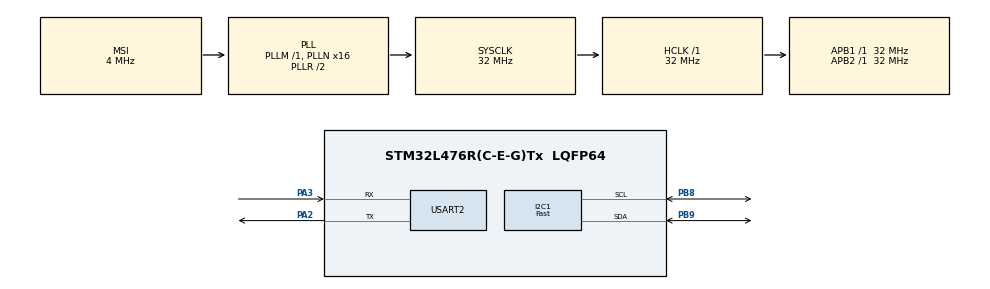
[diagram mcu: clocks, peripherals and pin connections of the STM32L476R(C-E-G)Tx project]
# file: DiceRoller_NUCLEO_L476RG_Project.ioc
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I2C1.I2C_Speed_Mode=I2C_Fast
I2C1.Timing=0x0060112F
Mcu.Family=STM32L4
Mcu.Name=STM32L476R(C-E-G)Tx
Mcu.Package=LQFP64
NVIC.PriorityGroup=NVIC_PRIORITYGROUP_4
PA13\ (JTMS-SWDIO).Mode=Serial_Wire
PA13\ (JTMS-SWDIO).Signal=SYS_JTMS-SWDIO
PA14\ (JTCK-SWCLK).Mode=Serial_Wire
PA14\ (JTCK-SWCLK).Signal=SYS_JTCK-SWCLK
PA2.Mode=Asynchronous
PA2.Signal=USART2_TX
PA3.Mode=Asynchronous
PA3.Signal=USART2_RX
PB8.Mode=I2C
PB8.Signal=I2C1_SCL
PB9.Mode=I2C
PB9.Signal=I2C1_SDA
PC14-OSC32_IN\ (PC14).Mode=LSE-External-Oscillator
PC14-OSC32_IN\ (PC14).Signal=RCC_OSC32_IN
PC15-OSC32_OUT\ (PC15).Mode=LSE-External-Oscillator
PC15-OSC32_OUT\ (PC15).Signal=RCC_OSC32_OUT
ProjectManager.HeapSize=0x200
ProjectManager.StackSize=0x400
ProjectManager.TargetToolchain=STM32CubeIDE
RCC.AHBFreq_Value=32000000
RCC.APB1Freq_Value=32000000
RCC.APB1TimFreq_Value=32000000
RCC.APB2Freq_Value=32000000
RCC.APB2TimFreq_Value=32000000
RCC.CortexFreq_Value=32000000
RCC.HCLKFreq_Value=32000000
RCC.HSE_VALUE=8000000
RCC.HSI_VALUE=16000000
RCC.MSI_VALUE=4000000
RCC.PLLN=16
RCC.SYSCLKFreq_VALUE=32000000
RCC.SYSCLKSource=RCC_SYSCLKSOURCE_PLLCLK
RCC.VCOOutputFreq_Value=64000000
USART2.VirtualMode-Asynchronous=VM_ASYNC
board=NUCLEO-L476RG

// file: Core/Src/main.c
/* USER CODE BEGIN Header */
/**
  ******************************************************************************
  * @file           : main.c
  * @brief          : Main program body
  ******************************************************************************
  * @attention
  *
  * Copyright (c) 2026 STMicroelectronics.
  * All rights reserved.
  *
  * This software is licensed under terms that can be found in the LICENSE file
  * in the root directory of this software component.
  * If no LICENSE file comes with this software, it is provided AS-IS.
  *
  ******************************************************************************
  */
#include <stdio.h>
#include <stdint.h>
#include "ssd1306_Custom.h"
#include "ssd1306_fonts_Custom.h"
#include "mpu6050.h"
/* USER CODE END Header */
#include "main.h"

I2C_HandleTypeDef hi2c1;

UART_HandleTypeDef huart2;

/* USER CODE BEGIN PV */

uint8_t mpu6050_profiler = 0;
uint8_t mpu6050_measurement_flag = 0;
/* USER CODE END PV */

void SystemClock_Config(void);
static void MX_GPIO_Init(void);
static void MX_USART2_UART_Init(void);
static void MX_I2C1_Init(void);
/* USER CODE BEGIN PFP */

// Retargetting Code for UART (Only for testing purposes across pins PA2 and PA3)
int __io_putchar(int ch){
	HAL_UART_Transmit(&huart2, (uint8_t*)&ch, 1, HAL_MAX_DELAY);
	return ch;
}

/* OLED Display (SSD1306 IC) Function Defs */
/* USER CODE END PFP */

int main(void)
{

  /* MCU Configuration--------------------------------------------------------*/

  /* Reset of all peripherals, Initializes the Flash interface and the Systick. */
  HAL_Init();

  /* Configure the system clock */
  SystemClock_Config();

  /* Initialize all configured peripherals */
  MX_GPIO_Init();
  MX_USART2_UART_Init();
  MX_I2C1_Init();
  /* USER CODE BEGIN 2 */

  // SSD1306 Test Code
  ssd1306_Init(hi2c1);

  // Test Screen Fill
//  ssd1306_FillBuffer();
//  ssd1306_UpdateScreen(hi2c1);
//  ssd1306_ClearBuffer();
//  ssd1306_UpdateScreen(hi2c1);

  // Test Drawing Pixels onto the screen (Form a tiny L)
//  ssd1306_DrawPixel(20, 20, White);
//  ssd1306_UpdateScreen(hi2c1);
//  ssd1306_DrawPixel(20, 21, White);
//  ssd1306_UpdateScreen(hi2c1);
//  ssd1306_DrawPixel(20, 22, White);
//  ssd1306_UpdateScreen(hi2c1);
//
//  ssd1306_DrawPixel(21, 20, White);
//  ssd1306_UpdateScreen(hi2c1);
//  ssd1306_DrawPixel(22, 20, White);
//  ssd1306_UpdateScreen(hi2c1);
//  ssd1306_DrawPixel(23, 20, White);
//  ssd1306_UpdateScreen(hi2c1);

  // Test Writing Characters to screen
//  ssd1306_SetFontCursor(30, 30);
//  ssd1306_WriteChar('i', Font_7x10);
//  ssd1306_UpdateScreen(hi2c1);
//  ssd1306_WriteChar(' ', Font_7x10);
//  ssd1306_UpdateScreen(hi2c1);
//  ssd1306_WriteChar('d', Font_7x10);
//  ssd1306_UpdateScreen(hi2c1);
//  ssd1306_WriteChar('i', Font_7x10);
//  ssd1306_UpdateScreen(hi2c1);
//  ssd1306_WriteChar('d', Font_7x10);
//  ssd1306_UpdateScreen(hi2c1);
//  ssd1306_WriteChar(' ', Font_7x10);
//  ssd1306_UpdateScreen(hi2c1);
//  ssd1306_WriteChar('i', Font_7x10);
//  ssd1306_UpdateScreen(hi2c1);
//  ssd1306_WriteChar('t', Font_7x10);
//  ssd1306_UpdateScreen(hi2c1);
//  ssd1306_WriteChar('\0', Font_7x10);
//  ssd1306_UpdateScreen(hi2c1);
//  ssd1306_SetScreen(1, hi2c1);

  // Test Printing out strings
  ssd1306_SetFontCursor(0, 10);
  ssd1306_WriteString("Dice Roller", Font_7x10);
  ssd1306_UpdateScreen(hi2c1);
  ssd1306_SetFontCursor(0, 20);
  ssd1306_WriteString("For DnD!!", Font_7x10);
  ssd1306_UpdateScreen(hi2c1);

  // Define
  /* USER CODE END 2 */

  /* Infinite loop */
  while (1)
  {
  }

}

void SystemClock_Config(void)
{
  RCC_OscInitTypeDef RCC_OscInitStruct = {0};
  RCC_ClkInitTypeDef RCC_ClkInitStruct = {0};

  /** Configure the main internal regulator output voltage
  */
  if (HAL_PWREx_ControlVoltageScaling(PWR_REGULATOR_VOLTAGE_SCALE1) != HAL_OK)
  {
    Error_Handler();
  }

  /** Configure LSE Drive Capability
  */
  HAL_PWR_EnableBkUpAccess();
  __HAL_RCC_LSEDRIVE_CONFIG(RCC_LSEDRIVE_LOW);

  /** Initializes the RCC Oscillators according to the specified parameters
  * in the RCC_OscInitTypeDef structure.
  */
  RCC_OscInitStruct.OscillatorType = RCC_OSCILLATORTYPE_LSE|RCC_OSCILLATORTYPE_MSI;
  RCC_OscInitStruct.LSEState = RCC_LSE_ON;
  RCC_OscInitStruct.MSIState = RCC_MSI_ON;
  RCC_OscInitStruct.MSICalibrationValue = 0;
  RCC_OscInitStruct.MSIClockRange = RCC_MSIRANGE_6;
  RCC_OscInitStruct.PLL.PLLState = RCC_PLL_ON;
  RCC_OscInitStruct.PLL.PLLSource = RCC_PLLSOURCE_MSI;
  RCC_OscInitStruct.PLL.PLLM = 1;
  RCC_OscInitStruct.PLL.PLLN = 16;
  RCC_OscInitStruct.PLL.PLLP = RCC_PLLP_DIV7;
  RCC_OscInitStruct.PLL.PLLQ = RCC_PLLQ_DIV2;
  RCC_OscInitStruct.PLL.PLLR = RCC_PLLR_DIV2;
  if (HAL_RCC_OscConfig(&RCC_OscInitStruct) != HAL_OK)
  {
    Error_Handler();
  }

  /** Initializes the CPU, AHB and APB buses clocks
  */
  RCC_ClkInitStruct.ClockType = RCC_CLOCKTYPE_HCLK|RCC_CLOCKTYPE_SYSCLK
                              |RCC_CLOCKTYPE_PCLK1|RCC_CLOCKTYPE_PCLK2;
  RCC_ClkInitStruct.SYSCLKSource = RCC_SYSCLKSOURCE_PLLCLK;
  RCC_ClkInitStruct.AHBCLKDivider = RCC_SYSCLK_DIV1;
  RCC_ClkInitStruct.APB1CLKDivider = RCC_HCLK_DIV1;
  RCC_ClkInitStruct.APB2CLKDivider = RCC_HCLK_DIV1;

  if (HAL_RCC_ClockConfig(&RCC_ClkInitStruct, FLASH_LATENCY_1) != HAL_OK)
  {
    Error_Handler();
  }

  /** Enable MSI Auto calibration
  */
  HAL_RCCEx_EnableMSIPLLMode();
}

static void MX_I2C1_Init(void)
{

  hi2c1.Instance = I2C1;
  hi2c1.Init.Timing = 0x0060112F;
  hi2c1.Init.OwnAddress1 = 0;
  hi2c1.Init.AddressingMode = I2C_ADDRESSINGMODE_7BIT;
  hi2c1.Init.DualAddressMode = I2C_DUALADDRESS_DISABLE;
  hi2c1.Init.OwnAddress2 = 0;
  hi2c1.Init.OwnAddress2Masks = I2C_OA2_NOMASK;
  hi2c1.Init.GeneralCallMode = I2C_GENERALCALL_DISABLE;
  hi2c1.Init.NoStretchMode = I2C_NOSTRETCH_DISABLE;
  if (HAL_I2C_Init(&hi2c1) != HAL_OK)
  {
    Error_Handler();
  }

  /** Configure Analogue filter
  */
  if (HAL_I2CEx_ConfigAnalogFilter(&hi2c1, I2C_ANALOGFILTER_ENABLE) != HAL_OK)
  {
    Error_Handler();
  }

  /** Configure Digital filter
  */
  if (HAL_I2CEx_ConfigDigitalFilter(&hi2c1, 0) != HAL_OK)
  {
    Error_Handler();
  }

}

static void MX_USART2_UART_Init(void)
{

  huart2.Instance = USART2;
  huart2.Init.BaudRate = 115200;
  huart2.Init.WordLength = UART_WORDLENGTH_8B;
  huart2.Init.StopBits = UART_STOPBITS_1;
  huart2.Init.Parity = UART_PARITY_NONE;
  huart2.Init.Mode = UART_MODE_TX_RX;
  huart2.Init.HwFlowCtl = UART_HWCONTROL_NONE;
  huart2.Init.OverSampling = UART_OVERSAMPLING_16;
  huart2.Init.OneBitSampling = UART_ONE_BIT_SAMPLE_DISABLE;
  huart2.AdvancedInit.AdvFeatureInit = UART_ADVFEATURE_NO_INIT;
  if (HAL_UART_Init(&huart2) != HAL_OK)
  {
    Error_Handler();
  }

}

static void MX_GPIO_Init(void)
{

  /* GPIO Ports Clock Enable */
  __HAL_RCC_GPIOC_CLK_ENABLE();
  __HAL_RCC_GPIOA_CLK_ENABLE();
  __HAL_RCC_GPIOB_CLK_ENABLE();

}

void Error_Handler(void)
{
  __disable_irq();
  while (1)
  {
  }
}
#ifdef USE_FULL_ASSERT
/**
  * @brief  Reports the name of the source file and the source line number
  *         where the assert_param error has occurred.
  * @param  file: pointer to the source file name
  * @param  line: assert_param error line source number
  * @retval None
  */
void assert_failed(uint8_t *file, uint32_t line)
{
  /* USER CODE BEGIN 6 */
  /* User can add his own implementation to report the file name and line number,
     ex: printf("Wrong parameters value: file %s on line %d\r\n", file, line) */
//	printf("Assertion Failed in File '%s' on Line %ld\r\n", file, line);
//	while(1){}
  /* USER CODE END 6 */
}
#endif /* USE_FULL_ASSERT */
